# FM33LC0XX register map
File version: 1.0
CPU: Cortex-M0 r1p0, little endian, no MPU, no FPU, 3 interrupt priority bits
Registers are 32-bit, read-write, reset 0x0 unless marked. A register's access mark holds for its fields unless they carry their own. Offsets are from the block's base; [hi:lo] are bit positions; {n}, {i} and the like mark numbered series.

## WWDT — WWDT module information
Base 0x40011800
0x00 CR wo — WWDT Control Register
  [7:0] CON — CON field description
0x04 CFGR reset 0x3 — WWDT Config Register
  [2:0] CFG — CFG field description
0x08 CNT ro — WWDT Counter Register
  [9:0] CNT — CNT field description
0x0C IER — WWDT Interrupt Enable Register
  [0] IE — IE field description
0x10 ISR — WWDT Interrupt Status Register
  [0] NOVF — NOVF field description
0x14 PSC ro — WWDT Prescaler Register
  [11:0] DIV_CNT — DIV_CNT field description

## FDET — FDET module information
Base 0x4001A838
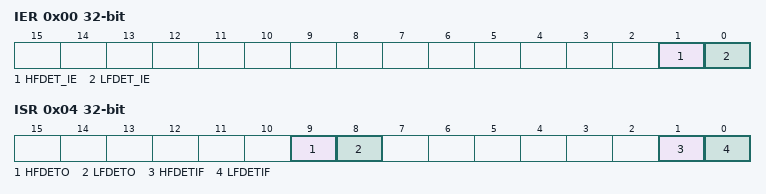
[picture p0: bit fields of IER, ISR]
0x00 IER — XTLF Oscillation Fail Detection Interrupt Enable Register
  [1] HFDET_IE — HFDET_IE field description
  [0] LFDET_IE — LFDET_IE field description
0x04 ISR access per field — XTLF Oscillation Fail Detection Interrupt Status Register
  [9] HFDETO ro — HFDETO field description
  [8] LFDETO ro — LFDETO field description
  [1] HFDETIF rw — HFDETIF field description
  [0] LFDETIF rw — LFDETIF field description

## SVD — SVD module information
Base 0x4001A824
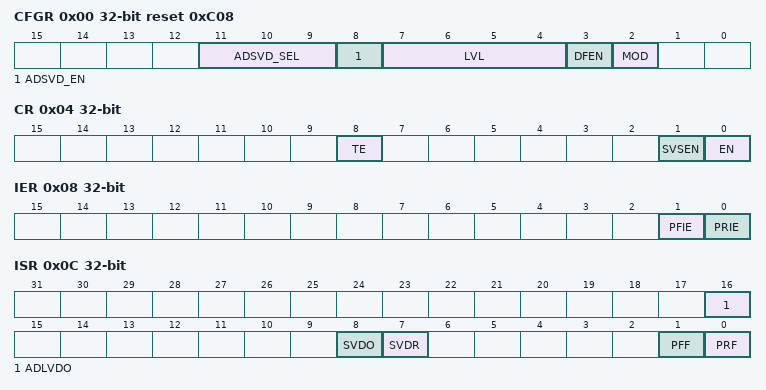
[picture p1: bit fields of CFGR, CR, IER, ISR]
0x00 CFGR reset 0xC08 — SVD Config Register
  [11:9] ADSVD_SEL — ADSVD_SEL field description
  [8] ADSVD_EN — ADSVD_EN field description
  [7:4] LVL — LVL field description
  [3] DFEN — DFEN field description
  [2] MOD — MOD field description
0x04 CR — SVD Control Register
  [8] TE — TE field description
  [1] SVSEN — SVSEN field description
  [0] EN — EN field description
0x08 IER — SVD Interrupt Enable Register
  [1] PFIE — PFIE field description
  [0] PRIE — PRIE field description
0x0C ISR access per field — SVD Interrupt Status Register
  [16] ADLVDO ro — ADLVDO field description
  [8] SVDO ro — SVDO field description
  [7] SVDR ro — SVDR field description
  [1] PFF rw — PFF field description
  [0] PRF rw — PRF field description
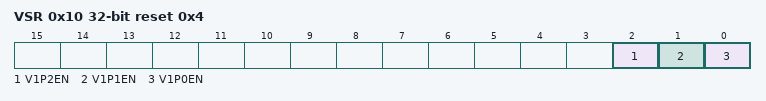
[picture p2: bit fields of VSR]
0x10 VSR reset 0x4 — SVD reference Voltage Select Register
  [2] V1P2EN — V1P2EN field description
  [1] V1P1EN — V1P1EN field description
  [0] V1P0EN — V1P0EN field description

## AES — AES module information
Base 0x4001B800
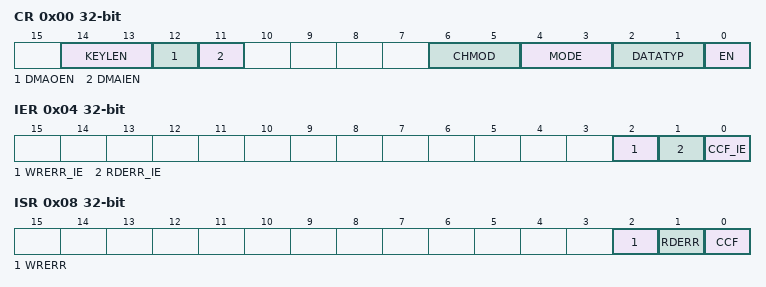
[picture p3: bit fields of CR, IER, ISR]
0x00 CR — AES Control Register
  [14:13] KEYLEN — KEYLEN field description
  [12] DMAOEN — DMAOEN field description
  [11] DMAIEN — DMAIEN field description
  [6:5] CHMOD — CHMOD field description
  [4:3] MODE — MODE field description
  [2:1] DATATYP — DATATYP field description
  [0] EN — EN field description
0x04 IER — AES Interrupt Enable Register
  [2] WRERR_IE — WRERR_IE field description
  [1] RDERR_IE — RDERR_IE field description
  [0] CCF_IE — CCF_IE field description
0x08 ISR — AES Interrupt Status Register
  [2] WRERR — WRERR field description
  [1] RDERR — RDERR field description
  [0] CCF — CCF field description
0x0C DIR — AES Data Input Register
  [31:0] DIN — DIN field description
0x10 DOR ro — AES Data Output Register
  [31:0] DOUT — DOUT field description
{0x14+4i} KEY{i} (i=0..7) — AES Key Register {i}
  [31:0] KEYx — KEYx field description
{0x34+4i} IVR{i} (i=0..3) — AES Initial Vector Register {i}
  [31:0] IVRx — IVRx field description

## RNGCTL — RNGCTL module information
Base 0x4001A868
0x00 CR — Random Number Generator Control Register
  [0] EN — EN field description

## RNG — RNG module information
Base 0x4001BC00
0x04 DOR ro — Random Number Generator Data Output Register
  [31:0] RNGOUT — RNGOUT field description
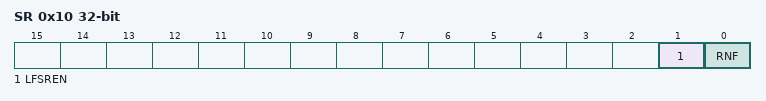
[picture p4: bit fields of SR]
0x10 SR access per field — Random Number Generator Status Register
  [1] LFSREN ro — LFSREN field description
  [0] RNF rw — RNF field description
0x14 CRCCR — CRC Control Register
  [0] CRCEN — CRCEN field description
0x18 CRCDIR — CRC Data input Register
  [31:0] CRCIN — CRCIN field description
0x1C CRCSR — CRC Status Register
  [0] CRCDONE — CRCDONE field description
